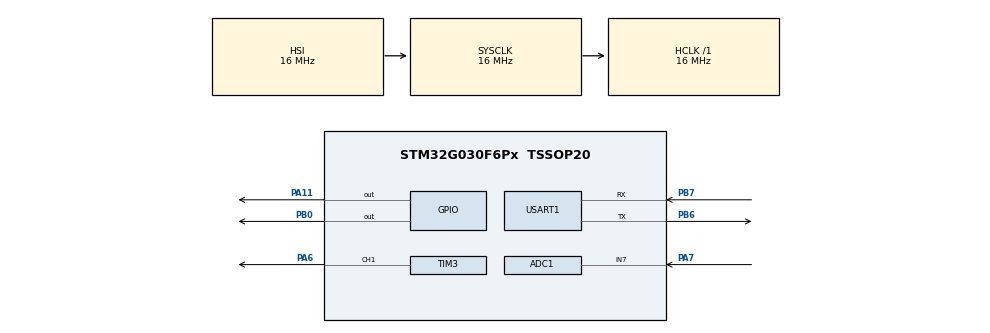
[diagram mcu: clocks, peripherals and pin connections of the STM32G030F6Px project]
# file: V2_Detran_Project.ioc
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ADC1.Channel-1\#ChannelRegularConversion=ADC_CHANNEL_7
ADC1.ContinuousConvMode=ENABLE
ADC1.NbrOfConversionFlag=1
ADC1.Rank-1\#ChannelRegularConversion=1
ADC1.SamplingTime-1\#ChannelRegularConversion=ADC_SAMPLINGTIME_COMMON_1
ADC1.SelectedChannel=ADC_CHANNEL_7
ADC1.master=1
Mcu.Family=STM32G0
Mcu.Name=STM32G030F6Px
Mcu.Package=TSSOP20
NVIC.TIM3_IRQn=true\:0\:0\:false\:false\:true\:true\:true\:true
NVIC.USART1_IRQn=true\:0\:0\:false\:false\:true\:true\:true\:true
PA11\ [PA9].Signal=GPIO_Output
PA13.Mode=Serial_Wire
PA13.Signal=SYS_SWDIO
PA14-BOOT0.Mode=Serial_Wire
PA14-BOOT0.Signal=SYS_SWCLK
PA14-BOOT0__PA15.StandardMode=true
PA6.Signal=S_TIM3_CH1
PA7.Mode=IN7
PA7.Signal=ADC1_IN7
PB0.Signal=GPIO_Output
PB0__PB1__PB2__PA8.StandardMode=true
PB3__PB4__PB5__PB6.StandardMode=true
PB6.Mode=Asynchronous
PB6.Signal=USART1_TX
PB7.Mode=Asynchronous
PB7.Signal=USART1_RX
PB7__PB8.StandardMode=true
PC14-OSC32_IN\ (PC14)__PB9.StandardMode=true
ProjectManager.HeapSize=0x200
ProjectManager.StackSize=0x400
ProjectManager.TargetToolchain=STM32CubeIDE
RCC.AHBFreq_Value=16000000
RCC.CortexFreq_Value=16000000
RCC.EXTERNAL_CLOCK_VALUE=12288000
RCC.HCLKFreq_Value=16000000
RCC.HSE_VALUE=8000000
RCC.HSI_VALUE=16000000
RCC.LSE_VALUE=32768
RCC.SYSCLKFreq_VALUE=16000000
RCC.VCOOutputFreq_Value=128000000
SH.S_TIM3_CH1.0=TIM3_CH1,PWM Generation1 CH1
TIM3.Channel-PWM\ Generation1\ CH1=TIM_CHANNEL_1
TIM3.Period=625
USART1.VirtualMode-Asynchronous=VM_ASYNC
board=custom

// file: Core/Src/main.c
/* USER CODE BEGIN Header */
/**
  ******************************************************************************
  * @file           : main.c
  * @brief          : Main program body
  ******************************************************************************
  * @attention
  *
  * Copyright (c) 2025 STMicroelectronics.
  * All rights reserved.
  *
  * This software is licensed under terms that can be found in the LICENSE file
  * in the root directory of this software component.
  * If no LICENSE file comes with this software, it is provided AS-IS.
  *
  ******************************************************************************
  */
/* USER CODE END Header */
#include "main.h"
#include "string.h"
/* USER CODE BEGIN Includes */
#include "uart_cmd.h"
#include "motor_driver.h"
#include "voltage_reader.h"
/* USER CODE END Includes */

ADC_HandleTypeDef hadc1;

TIM_HandleTypeDef htim3;

UART_HandleTypeDef huart1;

void SystemClock_Config(void);
static void MX_GPIO_Init(void);
static void MX_ADC1_Init(void);
static void MX_TIM3_Init(void);
static void MX_USART1_UART_Init(void);

int main(void)
{

  /* MCU Configuration--------------------------------------------------------*/

  /* Reset of all peripherals, Initializes the Flash interface and the Systick. */
  HAL_Init();

  /* Configure the system clock */
  SystemClock_Config();

  /* Initialize all configured peripherals */
  MX_GPIO_Init();
  MX_ADC1_Init();
  MX_TIM3_Init();
  MX_USART1_UART_Init();
  /* USER CODE BEGIN 2 */
  /* Inicia conversão contínua do ADC1.
    * Essa chamada habilita o ADC para que HAL_ADC_PollForConversion()
    * passe a retornar o valor mais recente sem reiniciar o módulo. */
   HAL_ADC_Start(&hadc1);

   /* Envia mensagem inicial pela UART1 */
   HAL_UART_Transmit(&huart1,
                     (uint8_t *)"Sistema Iniciado\r\n",
                     strlen("Sistema Iniciado\r\n"),
                     HAL_MAX_DELAY);

   /* Habilita interrupção de recepção de 1 byte na UART1.
    * A cada byte recebido, entra em HAL_UART_RxCpltCallback(...). */
   HAL_UART_Receive_IT(&huart1, &uart_rx_byte, 1);

   /* Inicia o canal 1 de PWM do TIM3.
    * A partir daqui, __HAL_TIM_SET_COMPARE() passa a ter efeito. */
   HAL_TIM_PWM_Start(&htim3, TIM_CHANNEL_1);

   while (1)
   {
       /* Executa a rampa de PWM caso tenha sido requisitada */
       pwm_ramp_task();
   }
  /* USER CODE END 3 */
}

void SystemClock_Config(void)
{
  RCC_OscInitTypeDef RCC_OscInitStruct = {0};
  RCC_ClkInitTypeDef RCC_ClkInitStruct = {0};

  /** Configure the main internal regulator output voltage
  */
  HAL_PWREx_ControlVoltageScaling(PWR_REGULATOR_VOLTAGE_SCALE1);

  /** Initializes the RCC Oscillators according to the specified parameters
  * in the RCC_OscInitTypeDef structure.
  */
  RCC_OscInitStruct.OscillatorType = RCC_OSCILLATORTYPE_HSI;
  RCC_OscInitStruct.HSIState = RCC_HSI_ON;
  RCC_OscInitStruct.HSIDiv = RCC_HSI_DIV1;
  RCC_OscInitStruct.HSICalibrationValue = RCC_HSICALIBRATION_DEFAULT;
  RCC_OscInitStruct.PLL.PLLState = RCC_PLL_NONE;
  if (HAL_RCC_OscConfig(&RCC_OscInitStruct) != HAL_OK)
  {
    Error_Handler();
  }

  /** Initializes the CPU, AHB and APB buses clocks
  */
  RCC_ClkInitStruct.ClockType = RCC_CLOCKTYPE_HCLK|RCC_CLOCKTYPE_SYSCLK
                              |RCC_CLOCKTYPE_PCLK1;
  RCC_ClkInitStruct.SYSCLKSource = RCC_SYSCLKSOURCE_HSI;
  RCC_ClkInitStruct.AHBCLKDivider = RCC_SYSCLK_DIV1;
  RCC_ClkInitStruct.APB1CLKDivider = RCC_HCLK_DIV1;

  if (HAL_RCC_ClockConfig(&RCC_ClkInitStruct, FLASH_LATENCY_0) != HAL_OK)
  {
    Error_Handler();
  }
}

static void MX_ADC1_Init(void)
{

  ADC_ChannelConfTypeDef sConfig = {0};

  /** Configure the global features of the ADC (Clock, Resolution, Data Alignment and number of conversion)
  */
  hadc1.Instance = ADC1;
  hadc1.Init.ClockPrescaler = ADC_CLOCK_SYNC_PCLK_DIV2;
  hadc1.Init.Resolution = ADC_RESOLUTION_12B;
  hadc1.Init.DataAlign = ADC_DATAALIGN_RIGHT;
  hadc1.Init.ScanConvMode = ADC_SCAN_DISABLE;
  hadc1.Init.EOCSelection = ADC_EOC_SINGLE_CONV;
  hadc1.Init.LowPowerAutoWait = DISABLE;
  hadc1.Init.LowPowerAutoPowerOff = DISABLE;
  hadc1.Init.ContinuousConvMode = ENABLE;
  hadc1.Init.NbrOfConversion = 1;
  hadc1.Init.ExternalTrigConv = ADC_SOFTWARE_START;
  hadc1.Init.ExternalTrigConvEdge = ADC_EXTERNALTRIGCONVEDGE_NONE;
  hadc1.Init.DMAContinuousRequests = DISABLE;
  hadc1.Init.Overrun = ADC_OVR_DATA_PRESERVED;
  hadc1.Init.SamplingTimeCommon1 = ADC_SAMPLETIME_1CYCLE_5;
  hadc1.Init.SamplingTimeCommon2 = ADC_SAMPLETIME_1CYCLE_5;
  hadc1.Init.OversamplingMode = DISABLE;
  hadc1.Init.TriggerFrequencyMode = ADC_TRIGGER_FREQ_HIGH;
  if (HAL_ADC_Init(&hadc1) != HAL_OK)
  {
    Error_Handler();
  }

  /** Configure Regular Channel
  */
  sConfig.Channel = ADC_CHANNEL_7;
  sConfig.Rank = ADC_REGULAR_RANK_1;
  sConfig.SamplingTime = ADC_SAMPLINGTIME_COMMON_1;
  if (HAL_ADC_ConfigChannel(&hadc1, &sConfig) != HAL_OK)
  {
    Error_Handler();
  }

}

static void MX_TIM3_Init(void)
{

  TIM_MasterConfigTypeDef sMasterConfig = {0};
  TIM_OC_InitTypeDef sConfigOC = {0};

  htim3.Instance = TIM3;
  htim3.Init.Prescaler = 0;
  htim3.Init.CounterMode = TIM_COUNTERMODE_UP;
  htim3.Init.Period = 625;
  htim3.Init.ClockDivision = TIM_CLOCKDIVISION_DIV1;
  htim3.Init.AutoReloadPreload = TIM_AUTORELOAD_PRELOAD_DISABLE;
  if (HAL_TIM_PWM_Init(&htim3) != HAL_OK)
  {
    Error_Handler();
  }
  sMasterConfig.MasterOutputTrigger = TIM_TRGO_RESET;
  sMasterConfig.MasterSlaveMode = TIM_MASTERSLAVEMODE_DISABLE;
  if (HAL_TIMEx_MasterConfigSynchronization(&htim3, &sMasterConfig) != HAL_OK)
  {
    Error_Handler();
  }
  sConfigOC.OCMode = TIM_OCMODE_PWM1;
  sConfigOC.Pulse = 0;
  sConfigOC.OCPolarity = TIM_OCPOLARITY_HIGH;
  sConfigOC.OCFastMode = TIM_OCFAST_DISABLE;
  if (HAL_TIM_PWM_ConfigChannel(&htim3, &sConfigOC, TIM_CHANNEL_1) != HAL_OK)
  {
    Error_Handler();
  }
  HAL_TIM_MspPostInit(&htim3);

}

static void MX_USART1_UART_Init(void)
{

  huart1.Instance = USART1;
  huart1.Init.BaudRate = 115200;
  huart1.Init.WordLength = UART_WORDLENGTH_8B;
  huart1.Init.StopBits = UART_STOPBITS_1;
  huart1.Init.Parity = UART_PARITY_NONE;
  huart1.Init.Mode = UART_MODE_TX_RX;
  huart1.Init.HwFlowCtl = UART_HWCONTROL_NONE;
  huart1.Init.OverSampling = UART_OVERSAMPLING_16;
  huart1.Init.OneBitSampling = UART_ONE_BIT_SAMPLE_DISABLE;
  huart1.Init.ClockPrescaler = UART_PRESCALER_DIV1;
  huart1.AdvancedInit.AdvFeatureInit = UART_ADVFEATURE_NO_INIT;
  if (HAL_UART_Init(&huart1) != HAL_OK)
  {
    Error_Handler();
  }
  if (HAL_UARTEx_SetTxFifoThreshold(&huart1, UART_TXFIFO_THRESHOLD_1_8) != HAL_OK)
  {
    Error_Handler();
  }
  if (HAL_UARTEx_SetRxFifoThreshold(&huart1, UART_RXFIFO_THRESHOLD_1_8) != HAL_OK)
  {
    Error_Handler();
  }
  if (HAL_UARTEx_DisableFifoMode(&huart1) != HAL_OK)
  {
    Error_Handler();
  }

}

static void MX_GPIO_Init(void)
{
  GPIO_InitTypeDef GPIO_InitStruct = {0};

  /* GPIO Ports Clock Enable */
  __HAL_RCC_GPIOB_CLK_ENABLE();
  __HAL_RCC_GPIOA_CLK_ENABLE();

  /*Configure GPIO pin Output Level */
  HAL_GPIO_WritePin(GPIOB, GPIO_PIN_0, GPIO_PIN_RESET);

  /*Configure GPIO pin Output Level */
  HAL_GPIO_WritePin(GPIOA, GPIO_PIN_11, GPIO_PIN_RESET);

  /*Configure GPIO pin : PB0 */
  GPIO_InitStruct.Pin = GPIO_PIN_0;
  GPIO_InitStruct.Mode = GPIO_MODE_OUTPUT_PP;
  GPIO_InitStruct.Pull = GPIO_NOPULL;
  GPIO_InitStruct.Speed = GPIO_SPEED_FREQ_LOW;
  HAL_GPIO_Init(GPIOB, &GPIO_InitStruct);

  /*Configure GPIO pin : PA11 */
  GPIO_InitStruct.Pin = GPIO_PIN_11;
  GPIO_InitStruct.Mode = GPIO_MODE_OUTPUT_PP;
  GPIO_InitStruct.Pull = GPIO_NOPULL;
  GPIO_InitStruct.Speed = GPIO_SPEED_FREQ_LOW;
  HAL_GPIO_Init(GPIOA, &GPIO_InitStruct);

}

/* USER CODE END 4 */

void Error_Handler(void)
{
  __disable_irq();
  while (1)
  {
  }
}
